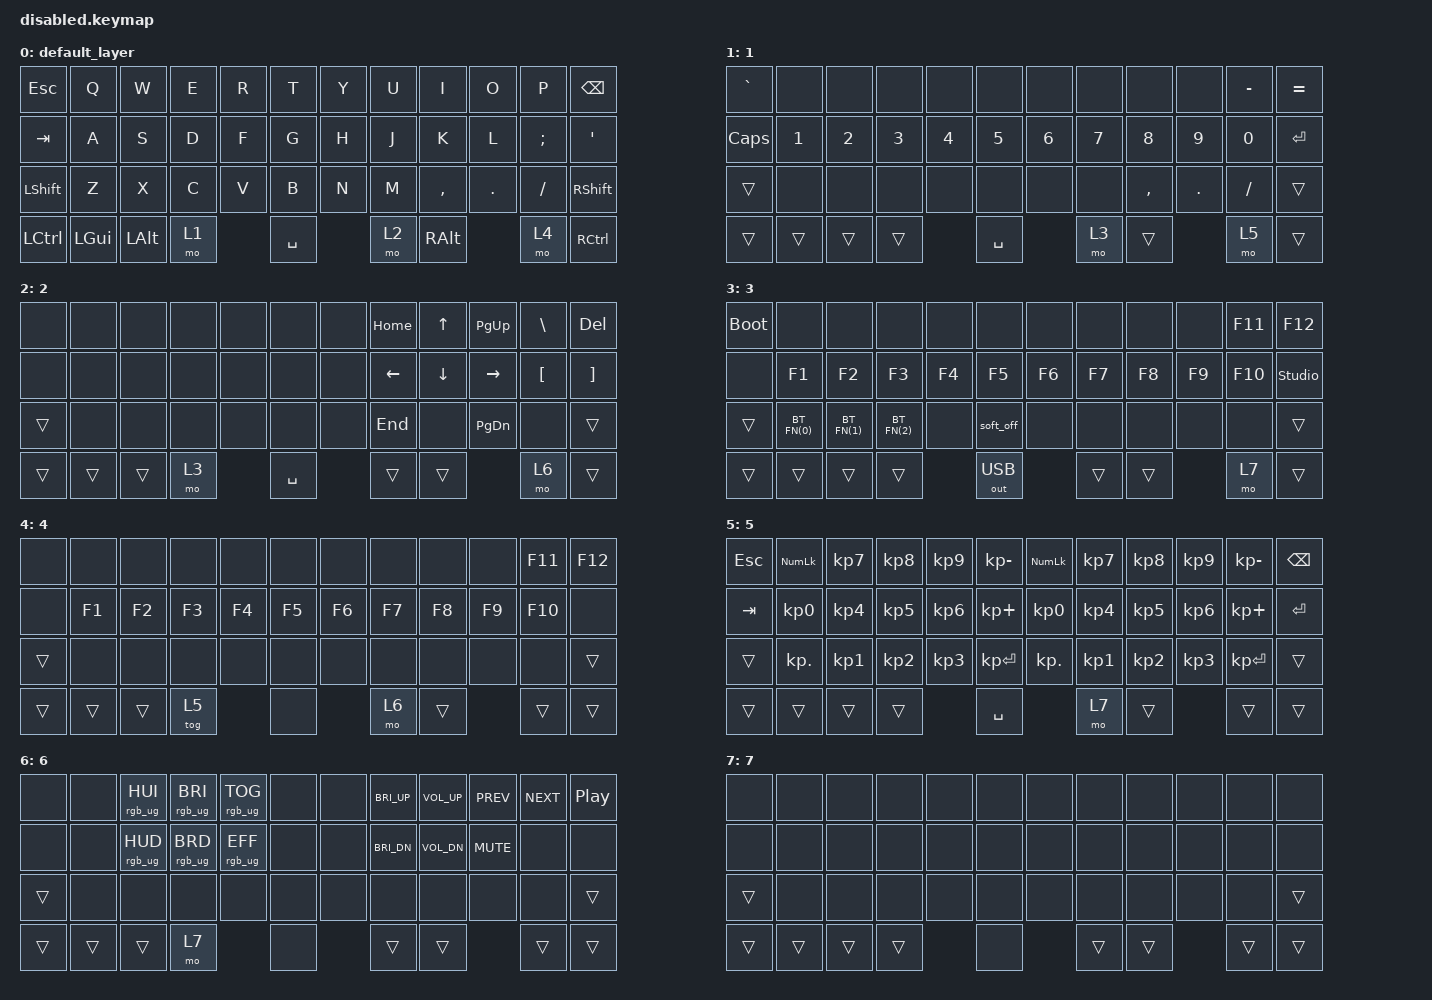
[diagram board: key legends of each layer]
#include <behaviors.dtsi>
#include <dt-bindings/zmk/keys.h>
#include <dt-bindings/zmk/bt.h>
#include <dt-bindings/zmk/outputs.h>
#include <dt-bindings/zmk/rgb.h>

#define BT_FN(profile) &bt_fn profile profile // Macro to apply bt_fn to the same profile

&soft_off {
    hold-time-ms = <1000>; // Only turn off when held for 1 second or longer
};

/ {
    macros {
        // Select, then output to BT profile
        bt_con: bt_con {
            compatible = "zmk,behavior-macro-one-param";
            wait-ms = <40>;
            tap-ms = <40>;
            #binding-cells = <1>;
            bindings
                = <&macro_param_1to2>
                , <&bt BT_SEL MACRO_PLACEHOLDER>
                , <&out OUT_BLE>
                ;
        };

        // Select, then clear, then output to BT profile
        bt_clr: bt_clr {
            compatible = "zmk,behavior-macro-one-param";
            wait-ms = <40>;
            tap-ms = <40>;
            #binding-cells = <1>;
            bindings
                = <&macro_param_1to2>
                , <&bt BT_SEL MACRO_PLACEHOLDER>
                , <&bt BT_CLR>
                , <&out OUT_BLE>
                ;
        };
    };

    behaviors {
        // Connect to selected BT profile on tap, forget selected BT profile and put into pairing mode on hold for 1 second or longer
        bt_fn: bt_fn {
            compatible = "zmk,behavior-hold-tap";
            #binding-cells = <2>;
            flavor = "hold-preferred";
            tapping-term-ms = <1000>;
            bindings = <&bt_clr>, <&bt_con>;
        };
    };

    keymap {
        compatible = "zmk,keymap";

        default_layer {
            bindings = <
                &kp ESC   &kp Q    &kp W    &kp E &kp R &kp T     &kp Y &kp U &kp I     &kp O   &kp P     &kp BSPC
                &kp TAB   &kp A    &kp S    &kp D &kp F &kp G     &kp H &kp J &kp K     &kp L   &kp SEMI  &kp SQT
                &kp LSHFT &kp Z    &kp X    &kp C &kp V &kp B     &kp N &kp M &kp COMMA &kp DOT &kp SLASH &kp RSHFT
                &kp LCTRL &kp LGUI &kp LALT &mo 1       &kp SPACE       &mo 2 &kp RALT          &mo 4     &kp RCTRL
            >;
        };

        1 {
            bindings = <
                &kp GRAVE &none  &none  &none  &none  &none     &none  &none  &none     &none   &kp MINUS &kp EQUAL
                &kp CAPS  &kp N1 &kp N2 &kp N3 &kp N4 &kp N5    &kp N6 &kp N7 &kp N8    &kp N9  &kp N0    &kp ENTER
                &trans    &none  &none  &none  &none  &none     &none  &none  &kp COMMA &kp DOT &kp SLASH &trans
                &trans    &trans &trans &trans        &kp SPACE        &mo 3  &trans            &mo 5    &trans
            >;
        };

        2 {
            bindings = <
                &none  &none  &none  &none  &none  &none     &none &kp HOME &kp UP   &kp PG_UP &kp BSLH &kp DEL
                &none  &none  &none  &none  &none  &none     &none &kp LEFT &kp DOWN &kp RIGHT &kp LBKT &kp RBKT
                &trans &none  &none  &none  &none  &none     &none &kp END  &none    &kp PG_DN &none    &trans
                &trans &trans &trans &mo 3         &kp SPACE       &trans   &trans             &mo 6    &trans
            >;
        };

        3 {
            bindings = <
                &bootloader &none    &none    &none    &none  &none        &none  &none  &none  &none  &kp F11 &kp F12
                &none       &kp F1   &kp F2   &kp F3   &kp F4 &kp F5       &kp F6 &kp F7 &kp F8 &kp F9 &kp F10 &studio_unlock
                &trans      BT_FN(0) BT_FN(1) BT_FN(2) &none  &soft_off    &none  &none  &none  &none  &none   &trans
                &trans      &trans   &trans   &trans          &out OUT_USB        &trans &trans        &mo 7   &trans
            >;
        };

        4 {
            bindings = <
                &none  &none  &none  &none  &none  &none  &none  &none  &none  &none  &kp F11 &kp F12
                &none  &kp F1 &kp F2 &kp F3 &kp F4 &kp F5 &kp F6 &kp F7 &kp F8 &kp F9 &kp F10 &none
                &trans &none  &none  &none  &none  &none  &none  &none  &none  &none  &none   &trans
                &trans &trans &trans &tog 5        &none         &mo 6  &trans        &trans  &trans
            >;
        };

        5 {
            bindings = <
                &kp ESC &kp KP_NUM &kp KP_N7 &kp KP_N8 &kp KP_N9 &kp KP_MINUS &kp KP_NUM &kp KP_N7 &kp KP_N8 &kp KP_N9 &kp KP_MINUS &kp BSPC
                &kp TAB &kp KP_N0  &kp KP_N4 &kp KP_N5 &kp KP_N6 &kp KP_PLUS  &kp KP_N0  &kp KP_N4 &kp KP_N5 &kp KP_N6 &kp KP_PLUS  &kp ENTER
                &trans  &kp KP_DOT &kp KP_N1 &kp KP_N2 &kp KP_N3 &kp KP_ENTER &kp KP_DOT &kp KP_N1 &kp KP_N2 &kp KP_N3 &kp KP_ENTER &trans
                &trans  &trans     &trans    &trans              &kp SPACE               &mo 7     &trans              &trans       &trans
            >;
        };

        6 {
            bindings = <
                &none  &none  &rgb_ug RGB_HUI &rgb_ug RGB_BRI &rgb_ug RGB_TOG &none &none &kp C_BRI_UP &kp C_VOL_UP &kp C_PREV &kp C_NEXT &kp C_PP
                &none  &none  &rgb_ug RGB_HUD &rgb_ug RGB_BRD &rgb_ug RGB_EFF &none &none &kp C_BRI_DN &kp C_VOL_DN &kp C_MUTE &none      &none
                &trans &none  &none           &none           &none           &none &none &none        &none        &none      &none      &trans
                &trans &trans &trans          &mo 7                           &none       &trans       &trans                  &trans     &trans
            >;
        };

        7 {
            bindings = <
                &none  &none  &none  &none  &none &none &none &none  &none  &none &none  &none
                &none  &none  &none  &none  &none &none &none &none  &none  &none &none  &none
                &trans &none  &none  &none  &none &none &none &none  &none  &none &none  &trans
                &trans &trans &trans &trans       &none       &trans &trans       &trans &trans
            >;
        };
    };
};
